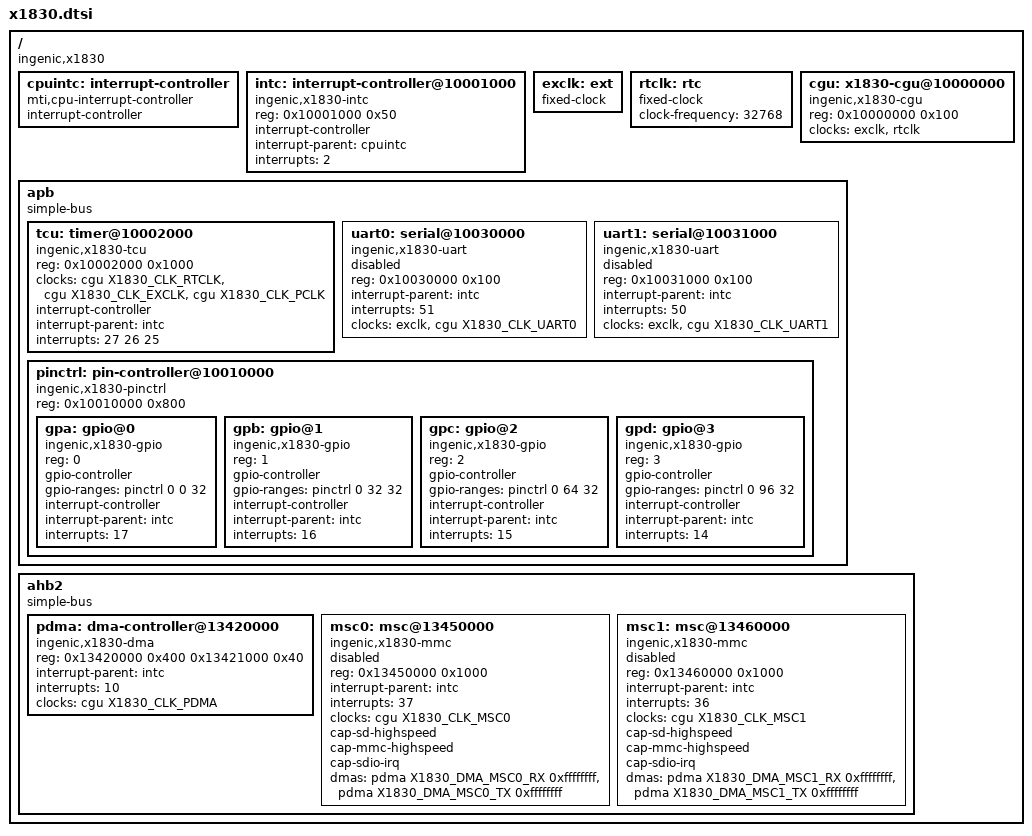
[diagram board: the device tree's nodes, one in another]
// SPDX-License-Identifier: GPL-2.0
#include <dt-bindings/clock/x1830-cgu.h>
#include <dt-bindings/dma/x1830-dma.h>

/ {
	#address-cells = <1>;
	#size-cells = <1>;
	compatible = "ingenic,x1830";

	cpuintc: interrupt-controller {
		#address-cells = <0>;
		#interrupt-cells = <1>;
		interrupt-controller;
		compatible = "mti,cpu-interrupt-controller";
	};

	intc: interrupt-controller@10001000 {
		compatible = "ingenic,x1830-intc", "ingenic,jz4780-intc";
		reg = <0x10001000 0x50>;

		interrupt-controller;
		#interrupt-cells = <1>;

		interrupt-parent = <&cpuintc>;
		interrupts = <2>;
	};

	exclk: ext {
		compatible = "fixed-clock";
		#clock-cells = <0>;
	};

	rtclk: rtc {
		compatible = "fixed-clock";
		#clock-cells = <0>;
		clock-frequency = <32768>;
	};

	cgu: x1830-cgu@10000000 {
		compatible = "ingenic,x1830-cgu";
		reg = <0x10000000 0x100>;

		#clock-cells = <1>;

		clocks = <&exclk>, <&rtclk>;
		clock-names = "ext", "rtc";
	};

	apb {
		compatible = "simple-bus";
		#address-cells = <1>;
		#size-cells = <1>;
		ranges = <>;

		tcu: timer@10002000 {
			compatible = "ingenic,x1830-tcu",
					 "ingenic,jz4770-tcu",
					 "simple-mfd";
			reg = <0x10002000 0x1000>;
			#address-cells = <1>;
			#size-cells = <1>;
			ranges = <0x0 0x10002000 0x1000>;

			#clock-cells = <1>;

			clocks = <&cgu X1830_CLK_RTCLK
				  &cgu X1830_CLK_EXCLK
				  &cgu X1830_CLK_PCLK>;
			clock-names = "rtc", "ext", "pclk";

			interrupt-controller;
			#interrupt-cells = <1>;

			interrupt-parent = <&intc>;
			interrupts = <27 26 25>;
		};

		uart0: serial@10030000 {
			compatible = "ingenic,x1830-uart", "ingenic,x1000-uart";
			reg = <0x10030000 0x100>;

			interrupt-parent = <&intc>;
			interrupts = <51>;

			clocks = <&exclk>, <&cgu X1830_CLK_UART0>;
			clock-names = "baud", "module";

			status = "disabled";
		};

		uart1: serial@10031000 {
			compatible = "ingenic,x1830-uart", "ingenic,x1000-uart";
			reg = <0x10031000 0x100>;

			interrupt-parent = <&intc>;
			interrupts = <50>;

			clocks = <&exclk>, <&cgu X1830_CLK_UART1>;
			clock-names = "baud", "module";

			status = "disabled";
		};

		pinctrl: pin-controller@10010000 {
			compatible = "ingenic,x1830-pinctrl";
			reg = <0x10010000 0x800>;
			#address-cells = <1>;
			#size-cells = <0>;

			gpa: gpio@0 {
				compatible = "ingenic,x1830-gpio";
				reg = <0>;

				gpio-controller;
				gpio-ranges = <&pinctrl 0 0 32>;
				#gpio-cells = <2>;

				interrupt-controller;
				#interrupt-cells = <2>;

				interrupt-parent = <&intc>;
				interrupts = <17>;
			};

			gpb: gpio@1 {
				compatible = "ingenic,x1830-gpio";
				reg = <1>;

				gpio-controller;
				gpio-ranges = <&pinctrl 0 32 32>;
				#gpio-cells = <2>;

				interrupt-controller;
				#interrupt-cells = <2>;

				interrupt-parent = <&intc>;
				interrupts = <16>;
			};

			gpc: gpio@2 {
				compatible = "ingenic,x1830-gpio";
				reg = <2>;

				gpio-controller;
				gpio-ranges = <&pinctrl 0 64 32>;
				#gpio-cells = <2>;

				interrupt-controller;
				#interrupt-cells = <2>;

				interrupt-parent = <&intc>;
				interrupts = <15>;
			};

			gpd: gpio@3 {
				compatible = "ingenic,x1830-gpio";
				reg = <3>;

				gpio-controller;
				gpio-ranges = <&pinctrl 0 96 32>;
				#gpio-cells = <2>;

				interrupt-controller;
				#interrupt-cells = <2>;

				interrupt-parent = <&intc>;
				interrupts = <14>;
			};
		};
	};

	ahb2 {
		compatible = "simple-bus";
		#address-cells = <1>;
		#size-cells = <1>;
		ranges = <>;

		pdma: dma-controller@13420000 {
			compatible = "ingenic,x1830-dma";
			reg = <0x13420000 0x400
				   0x13421000 0x40>;
			#dma-cells = <2>;

			interrupt-parent = <&intc>;
			interrupts = <10>;

			clocks = <&cgu X1830_CLK_PDMA>;
		};

		msc0: msc@13450000 {
			compatible = "ingenic,x1830-mmc", "ingenic,x1000-mmc";
			reg = <0x13450000 0x1000>;

			interrupt-parent = <&intc>;
			interrupts = <37>;

			clocks = <&cgu X1830_CLK_MSC0>;
			clock-names = "mmc";

			cap-sd-highspeed;
			cap-mmc-highspeed;
			cap-sdio-irq;

			dmas = <&pdma X1830_DMA_MSC0_RX 0xffffffff>,
				   <&pdma X1830_DMA_MSC0_TX 0xffffffff>;
			dma-names = "rx", "tx";

			status = "disabled";
		};

		msc1: msc@13460000 {
			compatible = "ingenic,x1830-mmc", "ingenic,x1000-mmc";
			reg = <0x13460000 0x1000>;

			interrupt-parent = <&intc>;
			interrupts = <36>;

			clocks = <&cgu X1830_CLK_MSC1>;
			clock-names = "mmc";

			cap-sd-highspeed;
			cap-mmc-highspeed;
			cap-sdio-irq;

			dmas = <&pdma X1830_DMA_MSC1_RX 0xffffffff>,
				   <&pdma X1830_DMA_MSC1_TX 0xffffffff>;
			dma-names = "rx", "tx";

			status = "disabled";
		};
	};
};
